# STM32F101_iown register map
Vendor: iown-homecontrol; Series: CM3; File version: 1.3
CPU: CM3 r1p1, little endian, no MPU, no FPU, VTOR, 4 interrupt priority bits
Registers are 32-bit, read-write, reset 0x0 unless marked. A register's access mark holds for its fields unless they carry their own. Offsets are from the block's base; [hi:lo] are bit positions; {n}, {i} and the like mark numbered series; 'fields as' and 'values as' point back to an identical list.

## PWR — Power control
Base 0x40007000
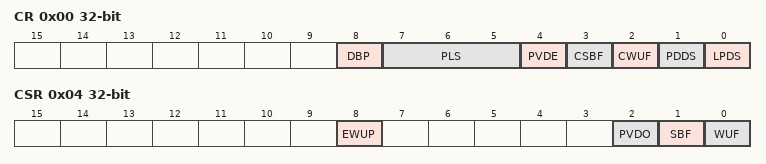
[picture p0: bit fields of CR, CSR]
0x00 CR — Power control register (PWR_CR)
  [8] DBP — Disable Backup Domain write protection
  [7:5] PLS — PVD Level Selection
  [4] PVDE — Power Voltage Detector Enable
  [3] CSBF — Clear STANDBY Flag
  [2] CWUF — Clear Wake-up Flag
  [1] PDDS — Power Down Deep Sleep
    0=STOP_MODE (Enter Stop mode when the CPU enters deepsleep); 1=STANDBY_MODE (Enter Standby mode when the CPU enters deepsleep)
  [0] LPDS — Low Power Deep Sleep
0x04 CSR — Power control register (PWR_CR)
  [8] EWUP — Enable WKUP pin
  [2] PVDO ro — PVD Output
  [1] SBF ro — STANDBY Flag
  [0] WUF ro — Wake-Up Flag

## GPIOA — General purpose I/O
Base 0x40010800
Same registers: GPIOB 0x40010C00, GPIOC 0x40011000, GPIOD 0x40011400, GPIOE 0x40011800, GPIOF 0x40011C00, GPIOG 0x40012000
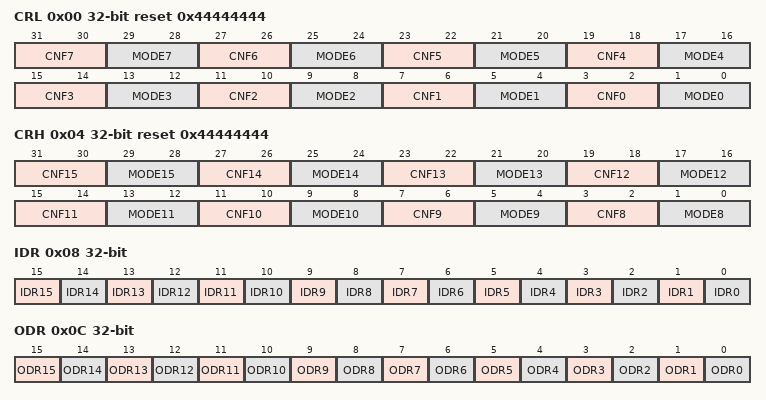
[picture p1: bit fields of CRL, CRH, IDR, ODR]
0x00 CRL reset 0x44444444 — Port configuration register low (GPIOn_CRL)
  [31:30] CNF7 — Port n.7 configuration bits
  [29:28] MODE7 — Port n.7 mode bits
  [27:26] CNF6 — Port n.6 configuration bits
  [25:24] MODE6 — Port n.6 mode bits
  [23:22] CNF5 — Port n.5 configuration bits
  [21:20] MODE5 — Port n.5 mode bits
  [19:18] CNF4 — Port n.4 configuration bits
  [17:16] MODE4 — Port n.4 mode bits
  [15:14] CNF3 — Port n.3 configuration bits
  [13:12] MODE3 — Port n.3 mode bits
  [11:10] CNF2 — Port n.2 configuration bits
  [9:8] MODE2 — Port n.2 mode bits
  [7:6] CNF1 — Port n.1 configuration bits
  [5:4] MODE1 — Port n.1 mode bits
  [3:2] CNF0 — Port n.0 configuration bits
    0=PushPull (Analog mode / Push-Pull mode); 1=OpenDrain (Floating input (reset state) / Open Drain-Mode); 2=AltPushPull (Input with pull-up/pull-down / Alternate Function Push-Pull Mode); 3=AltOpenDrain (Alternate Function Open-Drain Mode)
  [1:0] MODE0 — Port n.0 mode bits
    0=Input mode (reset state); 1=Output mode 10 MHz; 2=Output2 (Output mode 2 MHz); 3=Output50 (Output mode 50 MHz)
0x04 CRH reset 0x44444444 — Port configuration register high (GPIOn_CRL)
  [31:30] CNF15 — Port n.15 configuration bits
  [29:28] MODE15 — Port n.15 mode bits
  [27:26] CNF14 — Port n.14 configuration bits
  [25:24] MODE14 — Port n.14 mode bits
  [23:22] CNF13 — Port n.13 configuration bits
  [21:20] MODE13 — Port n.13 mode bits
  [19:18] CNF12 — Port n.12 configuration bits
  [17:16] MODE12 — Port n.12 mode bits
  [15:14] CNF11 — Port n.11 configuration bits
  [13:12] MODE11 — Port n.11 mode bits
  [11:10] CNF10 — Port n.10 configuration bits
  [9:8] MODE10 — Port n.10 mode bits
  [7:6] CNF9 — Port n.9 configuration bits
  [5:4] MODE9 — Port n.9 mode bits
  [3:2] CNF8 — Port n.8 configuration bits
    values as CRL.CNF0
  [1:0] MODE8 — Port n.8 mode bits
    values as CRL.MODE0
0x08 IDR ro — Port input data register (GPIOn_IDR)
  [n] IDR{n} (n=1..15) — Port input data
  [0] IDR0 — Port input data
    on read: 0=Low (Input is logic low); 1=High (Input is logic high)
0x0C ODR — Port output data register (GPIOn_ODR)
  [n] ODR{n} (n=1..15) — Port output data
  [0] ODR0 — Port output data
    0=Low (Set output to logic low); 1=High (Set output to logic high)
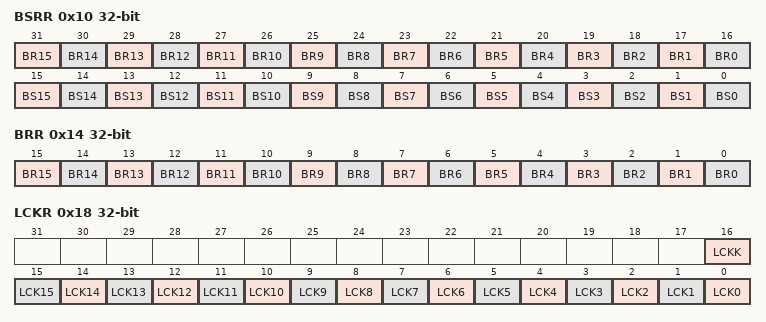
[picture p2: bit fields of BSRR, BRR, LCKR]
0x10 BSRR wo — Port bit set/reset register (GPIOn_BSRR)
  [n+16] BR{n} (n=1..15) — Reset bit {n}
  [16] BR0 — Reset bit 0
    on write: 1=Resets the corresponding ODRx bit
  [n] BS{n} (n=3..15) — Set bit {n}
  [2] BS2 — Set bit 1
  [1] BS1 — Set bit 1
  [0] BS0 — Set bit 0
    on write: 1=Set (Sets the corresponding ODRx bit)
0x14 BRR wo — Port bit reset register (GPIOn_BRR)
  [n] BR{n} (n=3..15) — Reset bit {n}
  [2] BR2 — Reset bit 1
  [1] BR1 — Reset bit 1
  [0] BR0 — Reset bit 0
    on write: 0=No action on the corresponding ODx bit; 1=Reset the ODx bit
0x18 LCKR — Port configuration lock register
  [16] LCKK — Lock key
    0=NotActive (Port configuration lock key not active); 1=Active (Port configuration lock key active)
  [n] LCK{n} (n=1..15) — Port A Lock bit {n}
  [0] LCK0 — Port A Lock bit 0
    0=Unlocked (Port configuration not locked); 1=Locked (Port configuration locked)
